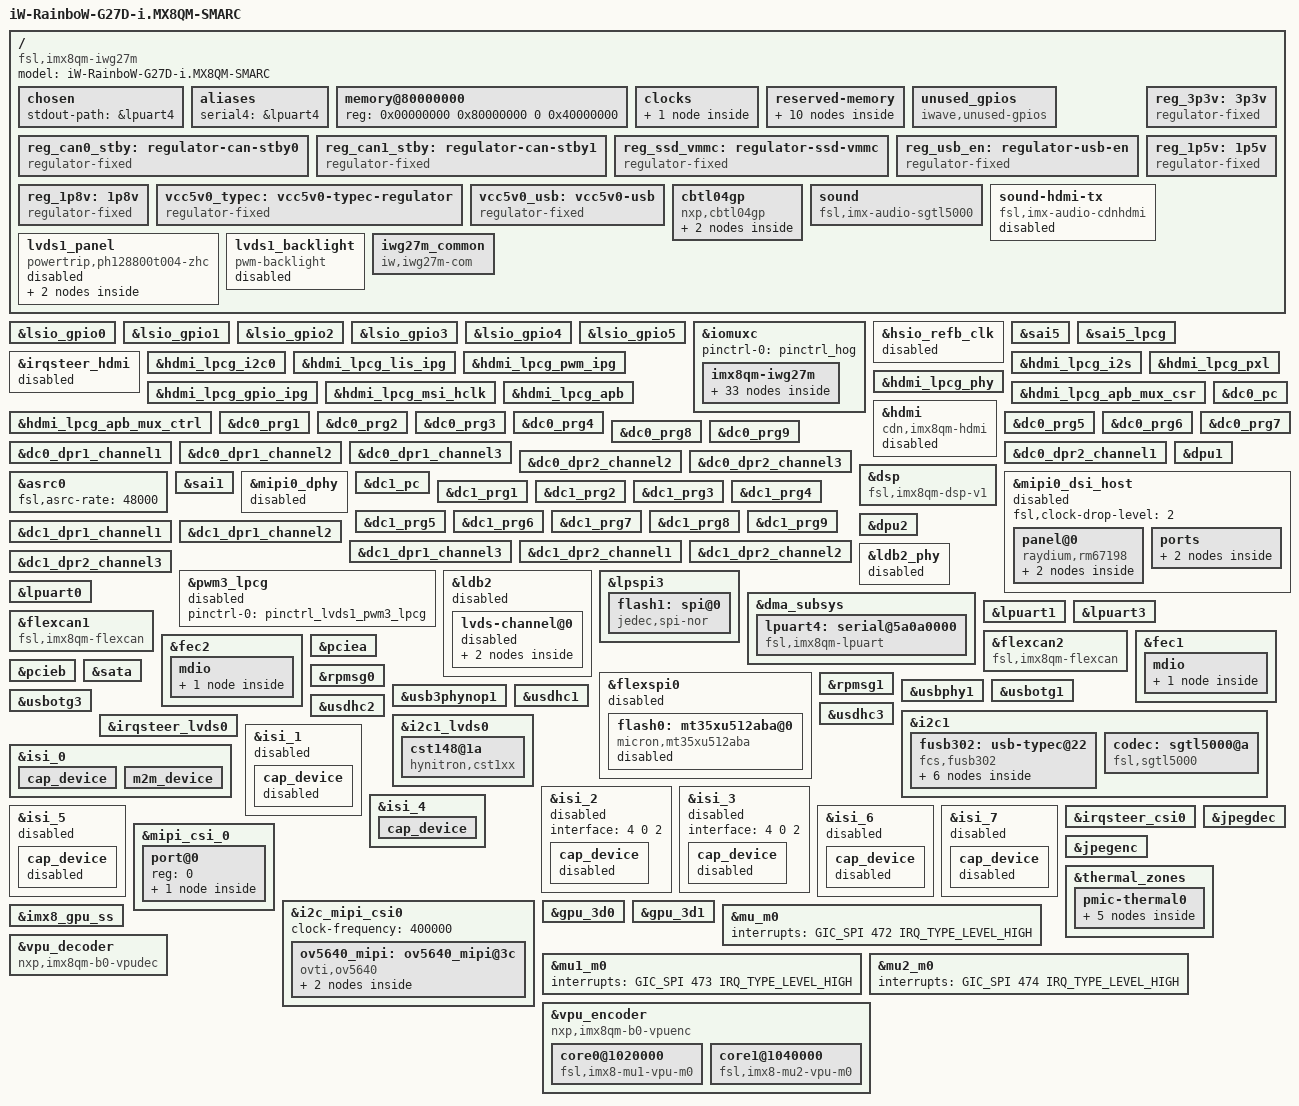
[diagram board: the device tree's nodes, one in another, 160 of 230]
/*
 * Copyright (c) 2020 iWave Systems Technologies Pvt. Ltd.
 *
 * This program is free software; you can redistribute it and/or
 * modify it under the terms of the GNU General Public License
 * as published by the Free Software Foundation; either version 2
 * of the License, or (at your option) any later version.
 *
 * This program is distributed in the hope that it will be useful,
 * but WITHOUT ANY WARRANTY; without even the implied warranty of
 * MERCHANTABILITY or FITNESS FOR A PARTICULAR PURPOSE.  See the
 * GNU General Public License for more details.
 */

#include <dt-bindings/usb/pd.h>
#include "imx8qm.dtsi"

/ {
	model = "iW-RainboW-G27D-i.MX8QM-SMARC";
	compatible = "fsl,imx8qm-iwg27m", "fsl,imx8qm";

	chosen {
                stdout-path = &lpuart4;
	};

	aliases {
		serial4 = &lpuart4;
	};

	memory@80000000 {
		device_type = "memory";
		reg = <0x00000000 0x80000000 0 0x40000000>;
	};

	clocks {
		#address-cells = <1>;
		#size-cells = <0>;

		audioclk: ext26Mz { /* SGTL5000: External Audio Clock */
			compatible = "fixed-clock";
			clock-frequency = <26000000>;
			reg=<0>;
			#clock-cells = <0>;
		};
	};

	reserved-memory {
		#address-cells = <2>;
		#size-cells = <2>;
		ranges;

		decoder_boot: decoder_boot@0x84000000 {
			no-map;
			reg = <0 0x84000000 0 0x2000000>;
		};
		encoder_boot: encoder_boot@0x86000000 {
			no-map;
			reg = <0 0x86000000 0 0x400000>;
		};
		/*
		 * reserved-memory layout
		 * 0x8800_0000 ~ 0x8FFF_FFFF is reserved for M4
		 * Shouldn't be used at A core and Linux side.
		 *
		 */
		m4_reserved: m4@0x88000000 {
			no-map;
			reg = <0 0x88000000 0 0x8000000>;
		};
		rpmsg_reserved: rpmsg@0x90000000 {
			no-map;
			reg = <0 0x90000000 0 0x400000>;
		};
		rpmsg_dma_reserved:rpmsg_dma@0x90400000 {
			compatible = "shared-dma-pool";
			no-map;
			reg = <0 0x90400000 0 0x100000>;
		};
		decoder_rpc: decoder_rpc@0x92000000 {
			no-map;
			reg = <0 0x92000000 0 0x200000>;
		};
		encoder_rpc: encoder_rpc@0x92200000 {
			no-map;
			reg = <0 0x92200000 0 0x200000>;
		};
		dsp_reserved: dsp@0x92400000 {
			no-map;
			reg = <0 0x92400000 0 0x2000000>;
		};
		encoder_reserved: encoder_reserved@0x94400000 {
			no-map;
			reg = <0 0x94400000 0 0x800000>;
		};

		/* global autoconfigured region for contiguous allocations */
		linux,cma {
			compatible = "shared-dma-pool";
			reusable;
			size = <0 0x3c000000>;
			alloc-ranges = <0 0x96000000 0 0x3c000000>;
			linux,cma-default;
		};

	};

	unused_gpios: unused_gpios { /* GPIO: Setting Unused GPIOs as input pins */
		compatible = "iwave,unused-gpios";
		pinctrl-names = "default";
		pinctrl-0 = <&pinctrl_unused_gpio>;
		status = "okay";  
	};

	reg_can0_stby: regulator-can-stby0 { /* CAN: CAN0 Standby Regulator */
		compatible = "regulator-fixed";
		regulator-name = "CAN0_STBY_1P8V";
		regulator-min-microvolt = <1800000>;
		regulator-max-microvolt = <1800000>;
		gpio = <&lsio_gpio1 27 GPIO_ACTIVE_HIGH>;
		regulator-always-on;
	};

	reg_can1_stby: regulator-can-stby1 { /* CAN: CAN1 Standby Regulator */
		compatible = "regulator-fixed";
		regulator-name = "CAN1_STBY_1P8V";
		regulator-min-microvolt = <1800000>;
		regulator-max-microvolt = <1800000>;
		gpio = <&lsio_gpio1 30 GPIO_ACTIVE_HIGH>;
		regulator-always-on;
	};

	reg_ssd_vmmc: regulator-ssd-vmmc { /* USDHC2: 3.3V VDD Enable Regulator */
		compatible = "regulator-fixed";
		regulator-name = "VDD_USDHC2_3P3V";
		regulator-min-microvolt = <3300000>;
		regulator-max-microvolt = <3300000>;
		gpio = <&lsio_gpio1 19 GPIO_ACTIVE_HIGH>;
		enable-active-high;
		regulator-always-on;
	};

	reg_usb_en: regulator-usb-en { /* USB: USB Hub Power Enable Regulator */
		compatible = "regulator-fixed";
		regulator-name = "VDD_USB_1P2V";
		regulator-min-microvolt = <1200000>;
		regulator-max-microvolt = <1200000>;
		regulator-type = "voltage";
		gpio = <&lsio_gpio1 21 GPIO_ACTIVE_HIGH>;
		enable-active-high;
		regulator-always-on;
	};

	reg_3p3v: 3p3v { /* Regulator: Fixed 3.3V Regulator */
		compatible = "regulator-fixed";
		regulator-name = "3P3V";
		regulator-min-microvolt = <3300000>;
		regulator-max-microvolt = <3300000>;
		regulator-always-on;
		regulator-boot-on;
	};

	reg_1p5v: 1p5v { /* Regulator: Fixed 1.5V Regulator */
		compatible = "regulator-fixed";
		regulator-name = "1P5V";
		regulator-min-microvolt = <1500000>;
		regulator-max-microvolt = <1500000>;
		regulator-always-on;
	};

	reg_1p8v: 1p8v { /* Regulator: Fixed 1.8V Regulator */
		compatible = "regulator-fixed";
		regulator-name = "1P8V";
		regulator-min-microvolt = <1800000>;
		regulator-max-microvolt = <1800000>;
		regulator-always-on;
	};

	vcc5v0_typec: vcc5v0-typec-regulator {
		compatible = "regulator-fixed";
		pinctrl-names = "default";
		regulator-name = "vcc5v0_typec";
		regulator-always-on;
		vin-supply = <&vcc5v0_usb>;
	};

	vcc5v0_usb: vcc5v0-usb {
		compatible = "regulator-fixed";
		regulator-name = "vcc5v0_usb";
		regulator-always-on;
		regulator-boot-on;
		regulator-min-microvolt = <5000000>;
		regulator-max-microvolt = <5000000>;
	};

	cbtl04gp {
		compatible = "nxp,cbtl04gp";
		pinctrl-names = "default";
		pinctrl-0 = <&pinctrl_typec_mux>;
		switch-gpios = <&lsio_gpio4 11 GPIO_ACTIVE_LOW>;
		orientation-switch;

		port {
			usb_data_ss: endpoint {
			remote-endpoint = <&typec_con_ss>;
			};
		};
        };

	sound { /* SGTL5000: Audio Codec */
		compatible = "fsl,imx-audio-sgtl5000";
		model = "sgtl5000-audio";
		ssi-controller = <&sai1>;
		audio-codec = <&codec>;
		audio-routing = "MIC_IN", "Mic Jack",
				"Mic Jack", "Mic Bias",
				"Headphone Jack", "HP_OUT",
				"LINE_IN", "Line In Jack";
	};

	sound-hdmi-tx { /* HDMI: HDMI TX Audio */
		compatible = "fsl,imx-audio-cdnhdmi";
		model = "imx-audio-hdmi-tx";
		audio-cpu = <&sai5>;
		protocol = <1>;
		hdmi-out;
		status = "disabled";
	};

	lvds1_panel { /* LVDS1: LVDS panel */
		compatible = "powertrip,ph128800t004-zhc";
		backlight = <&lvds1_backlight>;
		pinctrl-names = "default";
		pinctrl-0 = <&pinctrl_lvds1>;
		power-supply = <&reg_1p8v>;
		enable-gpios = <&lsio_gpio5 0 GPIO_ACTIVE_HIGH>;
		status = "disabled";

		port {
			panel_lvds1_in: endpoint {
				remote-endpoint = <&lvds1_out>;
			};
		};
	};

	lvds1_backlight: lvds1_backlight { /* LVDS1: LVDS Backlight Enable */
		compatible = "pwm-backlight";
		pwms = <&pwm3_lpcg 0 100000 0>;
		power-supply = <&reg_1p8v>;

		brightness-levels = < 0  1  2  3  4  5  6  7  8  9
				     10 11 12 13 14 15 16 17 18 19
				     20 21 22 23 24 25 26 27 28 29
				     30 31 32 33 34 35 36 37 38 39
				     40 41 42 43 44 45 46 47 48 49
				     50 51 52 53 54 55 56 57 58 59
				     60 61 62 63 64 65 66 67 68 69
				     70 71 72 73 74 75 76 77 78 79
				     80 81 82 83 84 85 86 87 88 89
				     90 91 92 93 94 95 96 97 98 99
				    100>;
		default-brightness-level = <100>;
		status = "disabled";
	};

	/* SoC Board Setttings : Setting Board Configuration GPIOs */
	iwg27m_common {
		compatible = "iw,iwg27m-com";
		pinctrl-names = "default";
		pinctrl-0 = <&pinctrl_board_cfg>;
		som-rev-gpios = <&lsio_gpio1 5 0>, <&lsio_gpio1 13 0>, <&lsio_gpio1 12 0>,  <&lsio_gpio1 11 0>,
			<&lsio_gpio0 6 0>, <&lsio_gpio0 7 0>, <&lsio_gpio0 11 0>;
		status = "okay";
	};
};

&lsio_gpio0 {
	status = "okay";
};

&lsio_gpio1 {
	status = "okay";
};

&lsio_gpio2 {
	status = "okay";
};

&lsio_gpio3 {
	status = "okay";
};

&lsio_gpio4 {
	status = "okay";
};

&lsio_gpio5 {
	status = "okay";
};

&iomuxc {
	pinctrl-names = "default";
	pinctrl-0 = <&pinctrl_hog>;

	imx8qm-iwg27m {
		pinctrl_hog: hoggrp { /* SDHC VSELECT Pin Configuration */
			fsl,pins = <
				IMX8QM_USDHC1_VSELECT_CONN_USDHC1_VSELECT		0x00000021
				IMX8QM_USDHC2_VSELECT_CONN_USDHC2_VSELECT		0x00000021
			>;
		};

		pinctrl_fec1: fec1grp { /* Ethernet0: IOMUX Pin Configuration */
			fsl,pins = <
				IMX8QM_COMP_CTL_GPIO_1V8_3V3_ENET_ENETB_PAD		0x000014a0
				IMX8QM_ENET0_MDC_CONN_ENET0_MDC				0x06000020
				IMX8QM_ENET0_MDIO_CONN_ENET0_MDIO			0x06000020
				IMX8QM_ENET0_RGMII_TX_CTL_CONN_ENET0_RGMII_TX_CTL	0x06000020
				IMX8QM_ENET0_RGMII_TXC_CONN_ENET0_RGMII_TXC		0x06000020
				IMX8QM_ENET0_RGMII_TXD0_CONN_ENET0_RGMII_TXD0		0x06000020
				IMX8QM_ENET0_RGMII_TXD1_CONN_ENET0_RGMII_TXD1		0x06000020
				IMX8QM_ENET0_RGMII_TXD2_CONN_ENET0_RGMII_TXD2		0x06000020
				IMX8QM_ENET0_RGMII_TXD3_CONN_ENET0_RGMII_TXD3		0x06000020
				IMX8QM_ENET0_RGMII_RXC_CONN_ENET0_RGMII_RXC		0x06000020
				IMX8QM_ENET0_RGMII_RX_CTL_CONN_ENET0_RGMII_RX_CTL	0x06000020
				IMX8QM_ENET0_RGMII_RXD0_CONN_ENET0_RGMII_RXD0		0x06000020
				IMX8QM_ENET0_RGMII_RXD1_CONN_ENET0_RGMII_RXD1		0x06000020
				IMX8QM_ENET0_RGMII_RXD2_CONN_ENET0_RGMII_RXD2		0x06000020
				IMX8QM_ENET0_RGMII_RXD3_CONN_ENET0_RGMII_RXD3		0x06000020
				IMX8QM_ENET0_REFCLK_125M_25M_CONN_ENET0_REFCLK_125M_25M	0x06000020
				IMX8QM_PCIE_CTRL0_CLKREQ_B_LSIO_GPIO4_IO27		0x06000021 /* Ethernet0 Interrupt */
				IMX8QM_PCIE_CTRL1_CLKREQ_B_LSIO_GPIO4_IO30		0x06000021 /* Ethernet0 Wake on LAN */
				IMX8QM_PCIE_CTRL1_WAKE_B_LSIO_GPIO4_IO31		0x06000021 /* Ethernet0 Reset */
			>;
		};

		pinctrl_fec2: fec2grp { /* Ethernet1: IOMUX Pin Configuration */
			fsl,pins = <
				IMX8QM_COMP_CTL_GPIO_1V8_3V3_ENET_ENETA_PAD		0x000014a0
				IMX8QM_ENET1_MDC_CONN_ENET1_MDC				0x06000020
				IMX8QM_ENET1_MDIO_CONN_ENET1_MDIO			0x06000020
				IMX8QM_ENET1_RGMII_TX_CTL_CONN_ENET1_RGMII_TX_CTL	0x00000060
				IMX8QM_ENET1_RGMII_TXC_CONN_ENET1_RGMII_TXC		0x00000060
				IMX8QM_ENET1_RGMII_TXD0_CONN_ENET1_RGMII_TXD0		0x00000060
				IMX8QM_ENET1_RGMII_TXD1_CONN_ENET1_RGMII_TXD1		0x00000060
				IMX8QM_ENET1_RGMII_TXD2_CONN_ENET1_RGMII_TXD2		0x00000060
				IMX8QM_ENET1_RGMII_TXD3_CONN_ENET1_RGMII_TXD3		0x00000060
				IMX8QM_ENET1_RGMII_RXC_CONN_ENET1_RGMII_RXC		0x00000060
				IMX8QM_ENET1_RGMII_RX_CTL_CONN_ENET1_RGMII_RX_CTL	0x00000060
				IMX8QM_ENET1_RGMII_RXD0_CONN_ENET1_RGMII_RXD0		0x00000060
				IMX8QM_ENET1_RGMII_RXD1_CONN_ENET1_RGMII_RXD1		0x00000060
				IMX8QM_ENET1_RGMII_RXD2_CONN_ENET1_RGMII_RXD2		0x00000060
				IMX8QM_ENET1_RGMII_RXD3_CONN_ENET1_RGMII_RXD3		0x00000060
				IMX8QM_ENET1_REFCLK_125M_25M_CONN_ENET1_REFCLK_125M_25M	0x00000060
				IMX8QM_MIPI_DSI1_I2C0_SCL_LSIO_GPIO1_IO20		0x06000021 /* Ethernet1 Reset */
				IMX8QM_MIPI_DSI0_I2C0_SCL_LSIO_GPIO1_IO16		0x06000021 /* Ethernet1 Wake on LAN */
				IMX8QM_MIPI_DSI0_I2C0_SDA_LSIO_GPIO1_IO17		0x06000021 /* Ethernet1 Interrupt */
			>;
		};

		pinctrl_flexspi0: flexspi0grp { /* FLEXSPI: MT35XU512ABA Octa-SPI IOMUX Pin Configuration */
			fsl,pins = <
				IMX8QM_QSPI0A_DATA0_LSIO_QSPI0A_DATA0			0x06000021
				IMX8QM_QSPI0A_DATA1_LSIO_QSPI0A_DATA1			0x06000021
				IMX8QM_QSPI0A_DATA2_LSIO_QSPI0A_DATA2			0x06000021
				IMX8QM_QSPI0A_DATA3_LSIO_QSPI0A_DATA3			0x06000021
				IMX8QM_QSPI0A_DQS_LSIO_QSPI0A_DQS			0x06000021
				IMX8QM_QSPI0A_SS0_B_LSIO_QSPI0A_SS0_B			0x06000021
				IMX8QM_QSPI0A_SS1_B_LSIO_QSPI0A_SS1_B			0x06000021
				IMX8QM_QSPI0A_SCLK_LSIO_QSPI0A_SCLK			0x06000021
				IMX8QM_QSPI0B_SCLK_LSIO_QSPI0B_SCLK			0x06000021
				IMX8QM_QSPI0B_DATA0_LSIO_QSPI0B_DATA0			0x06000021
				IMX8QM_QSPI0B_DATA1_LSIO_QSPI0B_DATA1			0x06000021
				IMX8QM_QSPI0B_DATA2_LSIO_QSPI0B_DATA2			0x06000021
				IMX8QM_QSPI0B_DATA3_LSIO_QSPI0B_DATA3			0x06000021
				IMX8QM_QSPI0B_DQS_LSIO_QSPI0B_DQS			0x06000021
				IMX8QM_QSPI0B_SS0_B_LSIO_QSPI0B_SS0_B			0x06000021
				IMX8QM_QSPI0B_SS1_B_LSIO_QSPI0B_SS1_B			0x06000021
			>;
		};

		pinctrl_lpspi3: lpspi3grp { /* LPSPI3: LPSPI3 IOMUX Pin Configuration */
			fsl,pins = <
				IMX8QM_SPI3_SCK_DMA_SPI3_SCK				0x0600004c
				IMX8QM_SPI3_SDO_DMA_SPI3_SDO				0x0600004c
				IMX8QM_SPI3_SDI_DMA_SPI3_SDI				0x0600004c
				IMX8QM_SPI3_CS0_LSIO_GPIO2_IO20				0x00000021
				IMX8QM_SPI3_CS1_DMA_SPI3_CS1				0x0600004c
			>;
		};

		pinctrl_flexcan1: flexcan0grp { /* CAN: FLEXCAN1 IOMUX Pin Configuration */
			fsl,pins = <
				IMX8QM_FLEXCAN0_TX_DMA_FLEXCAN0_TX			0x00000021
				IMX8QM_FLEXCAN0_RX_DMA_FLEXCAN0_RX			0x00000021
				IMX8QM_MIPI_CSI0_GPIO0_00_LSIO_GPIO1_IO27		0x00000021 /* FLEXCAN1 Power Down GPIO */
			>;
		};

		pinctrl_flexcan2: flexcan1grp { /* CAN: FLEXCAN2 IOMUX Pin Configuration */
			fsl,pins = <
				IMX8QM_FLEXCAN1_TX_DMA_FLEXCAN1_TX			0x00000021
				IMX8QM_FLEXCAN1_RX_DMA_FLEXCAN1_RX			0x00000021
				IMX8QM_MIPI_CSI1_GPIO0_00_LSIO_GPIO1_IO30		0x00000021 /* FLEXCAN2 Power Down GPIO */ 
			>;
		};

		pinctrl_lpuart0: lpuart0grp { /* LPUART0: DATA UART IOMUX Pin Configuration */
			fsl,pins = <
				IMX8QM_UART0_RX_DMA_UART0_RX				0x06000020
				IMX8QM_UART0_TX_DMA_UART0_TX				0x06000020
				IMX8QM_UART0_RTS_B_DMA_UART0_RTS_B			0x06000020
				IMX8QM_UART0_CTS_B_DMA_UART0_CTS_B			0x06000020
			>;
		};

		pinctrl_lpuart1: lpuart1grp { /* LPUART1: Bluetooth IOMUX Pin Configuration */
			fsl,pins = <
				IMX8QM_UART1_RX_DMA_UART1_RX				0x06000020
				IMX8QM_UART1_TX_DMA_UART1_TX				0x06000020
				IMX8QM_UART1_CTS_B_DMA_UART1_CTS_B			0x06000020
				IMX8QM_UART1_RTS_B_DMA_UART1_RTS_B			0x06000020
			>;
		};

		pinctrl_lpuart3: lpuart3grp { /* LPUART3: Debug UART IOMUX Pin Configuration */
			fsl,pins = <
				IMX8QM_M41_GPIO0_00_DMA_UART3_RX			0x06000020
				IMX8QM_M41_GPIO0_01_DMA_UART3_TX			0x06000020
			>;
		};

		pinctrl_lpuart4: lpuart4ggrp { /* LPUART4: Debug UART IOMUX Pin Configuration */
			fsl,pins = <
				IMX8QM_M40_GPIO0_00_DMA_UART4_RX			0x06000020
				IMX8QM_M40_GPIO0_01_DMA_UART4_TX			0x06000020
			>;
		};

		pinctrl_sai1: sai1grp { /* SGTL5000: SAI Audio IOMUX Pin Configuration */
			fsl,pins = <
				IMX8QM_SAI1_RXD_AUD_SAI1_RXD				0xc600004c
				IMX8QM_SAI1_TXC_AUD_SAI1_TXC				0xc600004c
				IMX8QM_SAI1_TXD_AUD_SAI1_TXD				0xc600004c
				IMX8QM_SAI1_TXFS_AUD_SAI1_TXFS				0xc600004c
			>;
		};

		pinctrl_hp_mic_detect: hp_mic_detect { /* SGTL5000: IOMUX Pin Configuration */
			fsl,pins = <
				IMX8QM_SIM0_IO_LSIO_GPIO0_IO02				0x00000021 /* HeadPhone Detect GPIO */
				IMX8QM_SIM0_GPIO0_00_LSIO_GPIO0_IO05			0x00000021 /* MicroPhone Detect GPIO */
				IMX8QM_MCLK_OUT0_AUD_ACM_MCLK_OUT0			0x0600004c
			>;
		};

		pinctrl_lpi2c1: lpi2c1grp { /* I2C1: IOMUX Pin Configuration */
			fsl,pins = <
				IMX8QM_GPT0_CLK_DMA_I2C1_SCL				0xc600004c
				IMX8QM_GPT0_CAPTURE_DMA_I2C1_SDA			0xc600004c
			>;
		};

		pinctrl_i2c1_lvds0: i2c1_lvds0grp { /* I2C1_LVDS0: Touch IOMUX Pin Configuration */
			fsl,pins = <
				IMX8QM_LVDS0_I2C0_SCL_LVDS0_I2C0_SCL			0xc600004c
				IMX8QM_LVDS0_I2C0_SDA_LVDS0_I2C0_SDA			0xc600004c
			>;
		};

		pinctrl_ts_active_iwg27m: touch { /* Touch: IOMUX Pin Configuration */
			fsl,pins = <
				IMX8QM_SIM0_RST_LSIO_GPIO0_IO01				0x00000021 /* Touch IRQ GPIO */
				IMX8QM_M41_I2C0_SCL_LSIO_GPIO0_IO10			0x00000021 /* Touch Reset GPIO */
			>;
		};

		pinctrl_pciea: pcieagrp{ /* PCIE: IOMUX Pin Configuration */
			fsl,pins = <
				IMX8QM_SIM0_POWER_EN_LSIO_GPIO0_IO04			0x00000021 /* PCIE W_DISABLE GPIO */
				IMX8QM_PCIE_CTRL0_WAKE_B_LSIO_GPIO4_IO28		0x00000021 /* PCIE Wake GPIO */
				IMX8QM_PCIE_CTRL0_PERST_B_LSIO_GPIO4_IO29		0x00000021 /* PCIE Reset GPIO */
			>;
		};

		pinctrl_type_c: usbtypec { /* USB3.0: FUSB Type-C IOMUX Pin Configuration */
			fsl,pins = <
				IMX8QM_SIM0_CLK_LSIO_GPIO0_IO00				0x00000021 /* Type-C IRQ GPIO */
			>;
		};

		pinctrl_typec_mux: usbtypec_ss { /* USB3.0: FUSB Type-C IOMUX Pin Configuration */
			fsl,pins = <
				IMX8QM_USDHC2_WP_LSIO_GPIO4_IO11			0x00000021 /* Type-C USB SS select GPIO */
			>;
		};

		pinctrl_usbotg1: usbotg1 { /* USBOTG1: USB OTG IOMUX Pin Configuration */
			fsl,pins = <
				IMX8QM_USB_SS3_TC0_LSIO_GPIO4_IO03			0x00000021 /* USB2.0 OTG Power GPIO */
			>;
		};

		pinctrl_usbotg3: usbotg3 { /* USBOTG3: USB Hub IOMUX Pin COnfiguration */
			fsl,pins = <
				IMX8QM_MIPI_DSI1_I2C0_SDA_LSIO_GPIO1_IO21		0x00000021 /* USB3.0 Hub Reset GPIO */
			>;
		};

		pinctrl_usdhc1: usdhc1grp { /* USDHC1: EMMC IOMUX Pin Configuration */
			fsl,pins = <
				IMX8QM_EMMC0_CLK_CONN_EMMC0_CLK				0x06000041
				IMX8QM_EMMC0_CMD_CONN_EMMC0_CMD				0x00000021
				IMX8QM_EMMC0_DATA0_CONN_EMMC0_DATA0			0x00000021
				IMX8QM_EMMC0_DATA1_CONN_EMMC0_DATA1			0x00000021
				IMX8QM_EMMC0_DATA2_CONN_EMMC0_DATA2			0x00000021
				IMX8QM_EMMC0_DATA3_CONN_EMMC0_DATA3			0x00000021
				IMX8QM_EMMC0_DATA4_CONN_EMMC0_DATA4			0x00000021
				IMX8QM_EMMC0_DATA5_CONN_EMMC0_DATA5			0x00000021
				IMX8QM_EMMC0_DATA6_CONN_EMMC0_DATA6			0x00000021
				IMX8QM_EMMC0_DATA7_CONN_EMMC0_DATA7			0x00000021
				IMX8QM_EMMC0_STROBE_CONN_EMMC0_STROBE			0x00000041
				IMX8QM_EMMC0_RESET_B_CONN_EMMC0_RESET_B			0x00000021
			>;
		};

		pinctrl_usdhc2_gpio: usdhc2grpgpio { /* USDHC2: Standard SD IOMUX Pin Configuration */
			fsl,pins = <
				IMX8QM_MIPI_DSI1_GPIO0_00_LSIO_GPIO1_IO22		0x00000021 /* Standard SD Write Protect */
				IMX8QM_MIPI_DSI1_GPIO0_01_LSIO_GPIO1_IO23		0x00000021 /* Standard SD Card Detect */
				IMX8QM_MIPI_DSI0_GPIO0_01_LSIO_GPIO1_IO19		0x00000021 /* Standard SD Power Enable */
			>;
		};

		pinctrl_usdhc2: usdhc2grp {
			fsl,pins = <
				IMX8QM_USDHC1_CLK_CONN_USDHC1_CLK			0x06000041
				IMX8QM_USDHC1_CMD_CONN_USDHC1_CMD			0x00000021
				IMX8QM_USDHC1_DATA0_CONN_USDHC1_DATA0			0x00000021
				IMX8QM_USDHC1_DATA1_CONN_USDHC1_DATA1			0x00000021
				IMX8QM_USDHC1_DATA2_CONN_USDHC1_DATA2			0x00000021
				IMX8QM_USDHC1_DATA3_CONN_USDHC1_DATA3			0x00000021
			>;
		};

		pinctrl_usdhc3_gpio: usdhc3grpgpio { /* USDHC3: IOMUX Pin Configuration */
			fsl,pins = <
				IMX8QM_ESAI0_TX2_RX3_LSIO_GPIO2_IO28			0x00000021 /* WIFI IRQ */
				IMX8QM_ESAI0_TX3_RX2_LSIO_GPIO2_IO29			0x00000021 /* WIFI RST */
				IMX8QM_ESAI0_TX4_RX1_LSIO_GPIO2_IO30			0x00000021 /* WIFI CORE_PDn */
				IMX8QM_USDHC2_CD_B_LSIO_GPIO4_IO12			0x00000021 /* SD Card Detect GPIO */	
				IMX8QM_SPI0_CS0_LSIO_GPIO3_IO05				0x00000021 /* WIFI WL_DEV_WAKE */
                                IMX8QM_SAI1_RXC_LSIO_GPIO3_IO12				0x00000021 /* WIFI WL_HOST_WAKE */
				IMX8QM_USDHC1_RESET_B_LSIO_GPIO4_IO07			0x00000021 /* WIFI PDn */
				IMX8QM_ESAI0_TX1_LSIO_GPIO2_IO27			0x00000021 /* BT_DEV_WAKE */
				IMX8QM_MCLK_IN0_LSIO_GPIO3_IO00				0x00000021 /* BT_HOST_WAKE */
			>;
		};

		pinctrl_usdhc3: usdhc3grp {
			fsl,pins = <
				IMX8QM_USDHC2_CLK_CONN_USDHC2_CLK			0x06000041
				IMX8QM_USDHC2_CMD_CONN_USDHC2_CMD			0x00000021
				IMX8QM_USDHC2_DATA0_CONN_USDHC2_DATA0			0x00000021
				IMX8QM_USDHC2_DATA1_CONN_USDHC2_DATA1			0x00000021
				IMX8QM_USDHC2_DATA2_CONN_USDHC2_DATA2			0x00000021
				IMX8QM_USDHC2_DATA3_CONN_USDHC2_DATA3			0x00000021
			>;
		};

		pinctrl_lvds1: lvds1grp { /* LVDS1: LVDS panel IOMUX Pin Configuration */
			fsl,pins = <
				IMX8QM_PCIE_CTRL1_PERST_B_LSIO_GPIO5_IO00		0x00000021 /* LVDS Power Enable GPIO */
			>;
		};

		pinctrl_lvds1_pwm3_lpcg: lvds1pwm3_lpcggrp { /* LVDS1: LVDS PWM IOMUX Pin Configuration */
			fsl,pins = <
				IMX8QM_GPT0_COMPARE_LSIO_PWM3_OUT			0x00000020
			>;
		};

		pinctrl_mipi_csi0: mipicsi0grp{ /* MIPI_CSI0: Camera MCLOCK IOMUX Pin Configuration */
			fsl,pins = <
				IMX8QM_MIPI_CSI0_MCLK_OUT_MIPI_CSI0_ACM_MCLK_OUT	0xC0000041
			>;
		};

		pinctrl_mipi_dsi: mipidsi { /* MIPI_DSI: LCD IOMUX Pin Configuration */
			fsl,pins = <
				IMX8QM_SIM0_PD_LSIO_GPIO0_IO03				0x00000021 /* MIPI-DSI Reset GPIO */
			>;
		};

		pinctrl_sata: sata { /* SATA: IOMUX Pin Configuration */
			fsl,pins = <
				IMX8QM_MIPI_DSI0_GPIO0_00_LSIO_GPIO1_IO18		0x00000021 /* SATA ACT LED GPIO */
			>;
		};

		pinctrl_board_cfg: brd_cfg { /* SoC Board Settings: IOMUX Pin Configuration */
			fsl,pins = <
				IMX8QM_LVDS0_GPIO01_LSIO_GPIO1_IO05			0x00000021
				IMX8QM_LVDS1_I2C0_SDA_LSIO_GPIO1_IO13			0x00000021
				IMX8QM_LVDS1_I2C0_SCL_LSIO_GPIO1_IO12			0x00000021
				IMX8QM_LVDS1_GPIO01_LSIO_GPIO1_IO11			0x00000021
				IMX8QM_M40_I2C0_SCL_LSIO_GPIO0_IO06			0x00000021
				IMX8QM_M40_I2C0_SDA_LSIO_GPIO0_IO07			0x00000021
				IMX8QM_M41_I2C0_SDA_LSIO_GPIO0_IO11			0x00000021
			>;
		};

		pinctrl_unused_gpio: unused_gpiogrp{ /* GPIO: Unused GPIOs IOMUX Pin Configuration */
			fsl,pins = <
				IMX8QM_LVDS0_GPIO00_LSIO_GPIO1_IO04			0x00000021
				IMX8QM_LVDS0_I2C1_SCL_LSIO_GPIO1_IO08			0x00000021
				IMX8QM_LVDS1_GPIO00_LSIO_GPIO1_IO10			0x00000021
				IMX8QM_LVDS1_I2C1_SCL_LSIO_GPIO1_IO14			0x00000021
				IMX8QM_LVDS1_I2C1_SDA_LSIO_GPIO1_IO15			0x00000021
				IMX8QM_MIPI_CSI1_MCLK_OUT_LSIO_GPIO1_IO29		0x00000021
				IMX8QM_MIPI_CSI1_I2C0_SCL_LSIO_GPIO2_IO00		0x00000021
				IMX8QM_MIPI_CSI1_I2C0_SDA_LSIO_GPIO2_IO01		0x00000021
				IMX8QM_HDMI_TX0_TS_SCL_LSIO_GPIO2_IO02			0x00000021
				IMX8QM_HDMI_TX0_TS_SDA_LSIO_GPIO2_IO03			0x00000021
				IMX8QM_ESAI1_FSR_LSIO_GPIO2_IO04			0x00000021
				IMX8QM_ESAI1_FST_LSIO_GPIO2_IO05			0x00000021
				IMX8QM_ESAI1_SCKR_LSIO_GPIO2_IO06			0x00000021
				IMX8QM_ESAI1_SCKT_LSIO_GPIO2_IO07			0x00000021
				IMX8QM_ESAI1_TX0_LSIO_GPIO2_IO08			0x00000021
				IMX8QM_ESAI1_TX1_LSIO_GPIO2_IO09			0x00000021
				IMX8QM_ESAI1_TX2_RX3_LSIO_GPIO2_IO10			0x00000021
				IMX8QM_ESAI1_TX3_RX2_LSIO_GPIO2_IO11			0x00000021
				IMX8QM_ESAI1_TX4_RX1_LSIO_GPIO2_IO12			0x00000021
				IMX8QM_ESAI1_TX5_RX0_LSIO_GPIO2_IO13			0x00000021
				IMX8QM_SPDIF0_RX_LSIO_GPIO2_IO14			0x00000021
				IMX8QM_SPDIF0_TX_LSIO_GPIO2_IO15			0x00000021
				IMX8QM_SPDIF0_EXT_CLK_LSIO_GPIO2_IO16			0x00000021
				IMX8QM_ESAI0_FSR_LSIO_GPIO2_IO22			0x00000021
				IMX8QM_ESAI0_SCKR_LSIO_GPIO2_IO24			0x00000021
				IMX8QM_SPI0_SCK_LSIO_GPIO3_IO02				0x00000021
				IMX8QM_SPI0_SDO_LSIO_GPIO3_IO03				0x00000021
				IMX8QM_SPI0_SDI_LSIO_GPIO3_IO04				0x00000021
				IMX8QM_SPI0_CS1_LSIO_GPIO3_IO06				0x00000021
				IMX8QM_SPI2_CS1_LSIO_GPIO3_IO11				0x00000021
				IMX8QM_SAI1_RXFS_LSIO_GPIO3_IO14			0x00000021
				IMX8QM_ADC_IN4_LSIO_GPIO3_IO22				0x00000021
				IMX8QM_ADC_IN5_LSIO_GPIO3_IO23				0x00000021
				IMX8QM_ADC_IN6_LSIO_GPIO3_IO24				0x00000021
				IMX8QM_ADC_IN7_LSIO_GPIO3_IO25				0x00000021
				IMX8QM_MLB_SIG_LSIO_GPIO3_IO26				0x00000021
				IMX8QM_MLB_CLK_LSIO_GPIO3_IO27				0x00000021
				IMX8QM_MLB_DATA_LSIO_GPIO3_IO28				0x00000021
				IMX8QM_FLEXCAN2_RX_LSIO_GPIO4_IO01			0x00000021
				IMX8QM_FLEXCAN2_TX_LSIO_GPIO4_IO02			0x00000021
				IMX8QM_USB_SS3_TC2_LSIO_GPIO4_IO05			0x00000021
				IMX8QM_USDHC2_RESET_B_LSIO_GPIO4_IO09			0x00000021
				IMX8QM_QSPI1A_SS0_B_LSIO_GPIO4_IO19			0x00000021
				IMX8QM_QSPI1A_SS1_B_LSIO_GPIO4_IO20			0x00000021
				IMX8QM_QSPI1A_SCLK_LSIO_GPIO4_IO21			0x00000021
				IMX8QM_QSPI1A_DQS_LSIO_GPIO4_IO22			0x00000021
				IMX8QM_QSPI1A_DATA3_LSIO_GPIO4_IO23			0x00000021
				IMX8QM_QSPI1A_DATA2_LSIO_GPIO4_IO24			0x00000021
				IMX8QM_QSPI1A_DATA1_LSIO_GPIO4_IO25			0x00000021
				IMX8QM_QSPI1A_DATA0_LSIO_GPIO4_IO26			0x00000021
				IMX8QM_USB_HSIC0_DATA_LSIO_GPIO5_IO01			0x00000021
				IMX8QM_USB_HSIC0_STROBE_LSIO_GPIO5_IO02			0x00000021
				IMX8QM_USDHC1_DATA4_LSIO_GPIO5_IO19			0x00000021
				IMX8QM_USDHC1_DATA5_LSIO_GPIO5_IO20			0x00000021
				IMX8QM_USDHC1_DATA6_LSIO_GPIO5_IO21			0x00000021
				IMX8QM_USDHC1_DATA7_LSIO_GPIO5_IO22			0x00000021
			>;
		};
	};
};

&hsio_refb_clk {
	status = "disabled";
};

&sai5 {
	status = "okay";
};

&sai5_lpcg {
        status = "okay";
};

&irqsteer_hdmi {
	status = "disabled";
};

&hdmi_lpcg_i2c0 {
	status = "okay";
};

&hdmi_lpcg_lis_ipg {
	status = "okay";
};

&hdmi_lpcg_pwm_ipg {
	status = "okay";
};

&hdmi_lpcg_i2s {
	status = "okay";
};

&hdmi_lpcg_gpio_ipg {
	status = "okay";
};

&hdmi_lpcg_msi_hclk {
	status = "okay";
};

&hdmi_lpcg_pxl {
	status = "okay";
};

&hdmi_lpcg_phy {
	status = "okay";
};

&hdmi_lpcg_apb_mux_csr {
	status = "okay";
};

&hdmi_lpcg_apb_mux_ctrl {
	status = "okay";
};

&hdmi_lpcg_apb {
	status = "okay";
};

&hdmi {
        compatible = "cdn,imx8qm-hdmi";
        lane-mapping = <0x93>;
	/* IWG27M: HDMI-DDC: Workaround for R3.X SOM DDC IO Voltage level */
        fsl,no_edid;
	status = "disabled";
};

&dc0_pc {
	status = "okay";
};

&dc0_prg1 {
	status = "okay";
};

&dc0_prg2 {
	status = "okay";
};

&dc0_prg3 {
	status = "okay";
};

&dc0_prg4 {
	status = "okay";
};

&dc0_prg5 {
	status = "okay";
};

&dc0_prg6 {
	status = "okay";
};

&dc0_prg7 {
	status = "okay";
};

&dc0_prg8 {
	status = "okay";
};

&dc0_prg9 {
	status = "okay";
};

&dc0_dpr1_channel1 {
	status = "okay";
};

&dc0_dpr1_channel2 {
	status = "okay";
};

&dc0_dpr1_channel3 {
	status = "okay";
};

&dc0_dpr2_channel1 {
	status = "okay";
};

&dc0_dpr2_channel2 {
	status = "okay";
};

&dc0_dpr2_channel3 {
	status = "okay";
};

&dpu1 {
	status = "okay";
};

&dsp {
	compatible = "fsl,imx8qm-dsp-v1";
	status = "okay";
};

&asrc0 {
	fsl,asrc-rate  = <48000>;
	status = "okay";
};

&sai1 { /* SGTL5000: Serial Audio Interface for SGTL5000 Audio Codec */
	assigned-clocks = <&clk IMX_SC_R_AUDIO_PLL_0 IMX_SC_PM_CLK_PLL>,
		<&clk IMX_SC_R_AUDIO_PLL_0 IMX_SC_PM_CLK_SLV_BUS>,
		<&clk IMX_SC_R_AUDIO_PLL_0 IMX_SC_PM_CLK_MST_BUS>,
		<&sai1_lpcg 0>; /* FIXME: should be sai1, original code is 0 */
	assigned-clock-rates = <786432000>, <49152000>, <12288000>, <49152000>;
	pinctrl-names = "default";
	pinctrl-0 = <&pinctrl_sai1>;
	status = "okay";
};

&mipi0_dphy { /* MIPI_DSI1: MIPI DSI Phy */
        status = "disabled";
};

&mipi0_dsi_host { /* MIPI_DSI1: MIPI DSI Host */
	fsl,clock-drop-level = <2>;
	status = "disabled";

	panel@0 {
		#address-cells = <1>;
		#size-cells = <0>;

		compatible = "raydium,rm67198";
		pinctrl-0 = <&pinctrl_mipi_dsi>;
		pinctrl-names = "default";
		reset-gpios = <&lsio_gpio0 3 GPIO_ACTIVE_LOW>;
		reg = <0>;
		dsi-lanes = <4>;
		video-mode = <2>;
		width-mm = <68>;
		height-mm = <121>;
		v3p3-supply = <&reg_3p3v>;
		v1p8-supply = <&reg_1p8v>;

		port@0 {
			reg = <0>;
			panel0_in: endpoint {
				remote-endpoint = <&mipi0_panel_out>;
			};
		};
	};

	ports {
		port@1 {
			reg = <1>;
			mipi0_panel_out: endpoint {
				remote-endpoint = <&panel0_in>;
			};
		};
	};
};

&dc1_pc {
	status = "okay";
};

&dc1_prg1 {
	status = "okay";
};

&dc1_prg2 {
	status = "okay";
};

&dc1_prg3 {
	status = "okay";
};

&dc1_prg4 {
	status = "okay";
};

&dc1_prg5 {
	status = "okay";
};

&dc1_prg6 {
	status = "okay";
};

&dc1_prg7 {
	status = "okay";
};

&dc1_prg8 {
	status = "okay";
};

&dc1_prg9 {
	status = "okay";
};

&dc1_dpr1_channel1 {
	status = "okay";
};

&dc1_dpr1_channel2 {
	status = "okay";
};

&dc1_dpr1_channel3 {
	status = "okay";
};

&dc1_dpr2_channel1 {
	status = "okay";
};

&dc1_dpr2_channel2 {
	status = "okay";
};

&dc1_dpr2_channel3 {
	status = "okay";
};

&dpu2 {
	status = "okay";
};

&pwm3_lpcg { /* LVDS1: LVDS PWM3 Control */
	pinctrl-names = "default";
	#pwm-cells = <2>;
	pinctrl-0 = <&pinctrl_lvds1_pwm3_lpcg>;
	status = "disabled";
};

&ldb2_phy { /* LVDS1: LVDS LDB Phy */
	status = "disabled";
};

&ldb2 { /* LVDS1: LVDS Channel-0 Port Enable */
	status = "disabled";

	lvds-channel@0 {
		fsl,data-mapping = "spwg";
		fsl,data-width = <24>;
		status = "disabled";
		port@1 {
			reg = <1>;

			lvds1_out: endpoint {
				remote-endpoint = <&panel_lvds1_in>;
			};
		};
	};
};

&lpspi3 { /* LPSPI3: SPI Flash Device */
        pinctrl-names = "default";
        pinctrl-0 = <&pinctrl_lpspi3>;
        cs-gpios = <&lsio_gpio2 20 GPIO_ACTIVE_LOW>;
        fsl,spi-num-chipselects = <1>;
        assigned-clock-rates = <80000000>;
        #address-cells = <1>;
        #size-cells = <0>;
	dma-names = "tx","rx";
	dmas = <&edma2 7 0 0>,
		<&edma2 6 0 1>;
	status = "okay";

	flash1: spi@0 { /* SST25WF020A SPI Flash */
		#address-cells = <1>;
		#size-cells = <1>;
		compatible = "jedec,spi-nor", "is25wp016d";
                spi-max-frequency = <40000000>;
                reg = <0>;
                spi-tx-bus-width = <1>;
                spi-rx-bus-width = <1>;
                m25p,fast-read;
		status = "okay";
	};
};

&dma_subsys {
	lpuart4: serial@5a0a0000 {
		compatible = "fsl,imx8qm-lpuart", "fsl,imx8qxp-lpuart";
		reg = <0x5a0a0000 0x1000>;
		interrupts = <GIC_SPI 349 IRQ_TYPE_LEVEL_HIGH>;
		interrupt-parent = <&gic>;
		clocks = <&uart4_lpcg 1>, <&uart4_lpcg 0>;
		clock-names = "ipg", "baud";
		assigned-clocks = <&clk IMX_SC_R_UART_4 IMX_SC_PM_CLK_PER>;
		assigned-clock-rates = <80000000>;
		power-domains = <&pd IMX_SC_R_UART_4>;
		power-domain-names = "uart";
		dma-names = "tx","rx";
		dmas = <&edma2 21 0 0>,
			<&edma2 20 0 1>;
	};
};

&lpuart0 { /* LPUART0: DATA UART */
	pinctrl-names = "default";
	pinctrl-0 = <&pinctrl_lpuart0>;
	dma-names = "tx","rx";
	power-domains = <&pd IMX_SC_R_UART_0>;
	dmas = <&edma2 13 0 0>,
	       <&edma2 12 0 1>;
	status = "okay";
};

&lpuart1 { /* LPUART1: Bluetooth */
	pinctrl-names = "default";
	pinctrl-0 = <&pinctrl_lpuart1>;
	port-number = <1>;
	status = "okay";
};

&lpuart3 { /* LPUART3: DATA UART */
        pinctrl-names = "default";
        pinctrl-0 = <&pinctrl_lpuart3>;
	power-domains = <&pd IMX_SC_R_UART_3>;
	dmas = <&edma2 19 0 0>,
	       <&edma2 18 0 1>;
        status = "okay";
};

&lpuart4 { /* LPUART4: Debug UART */
        pinctrl-names = "default";
        pinctrl-0 = <&pinctrl_lpuart4>;
	status = "okay";
};

&flexcan1 { /* CAN: FLEXCAN1 */
	pinctrl-names = "default";
	compatible = "fsl,imx8qm-flexcan"; 
	pinctrl-0 = <&pinctrl_flexcan1>;
	xceiver-supply = <&reg_can0_stby>;
	status = "okay";
};

&flexcan2 { /* CAN: FLEXCAN2 */
	pinctrl-names = "default";
	pinctrl-0 = <&pinctrl_flexcan2>;
	compatible = "fsl,imx8qm-flexcan"; 
	xceiver-supply = <&reg_can1_stby>;
	status = "okay";
};

&fec1 { /* FEC1: AR8031 PHY ENET 0 */
	pinctrl-names = "default";
	pinctrl-0 = <&pinctrl_fec1>;
	phy-mode = "rgmii-txid";
	phy-handle = <&ethphy0>;
	phy-reset-gpios = <&lsio_gpio4 31 GPIO_ACTIVE_LOW>;
	fsl,magic-packet;
	fsl,rgmii_rxc_dly;
	fsl,mii-exclusive;
	nvmem-cells = <&fec_mac0>;
	nvmem-cell-names = "mac-address";
	status = "okay";

	mdio {
		#address-cells = <1>;
		#size-cells = <0>;

		ethphy0: ethernet-phy@0 {
			compatible = "ethernet-phy-ieee802.3-c22";
			reg = <4>;
			at803x,eee-disabled;
			at803x,vddio-1p8v;
		};
	};
};

&fec2 { /* FEC2: AR8031 PHY ENET 1 */
	pinctrl-names = "default";
	pinctrl-0 = <&pinctrl_fec2>;
	phy-mode = "rgmii-txid";
	phy-handle = <&ethphy1>;
	phy-reset-gpios = <&lsio_gpio1 20 GPIO_ACTIVE_LOW>;
	fsl,magic-packet;
	fsl,rgmii_rxc_dly;
	fsl,mii-exclusive;
	nvmem-cells = <&fec_mac1>;
	nvmem-cell-names = "mac-address";
	status = "okay";

	mdio {
		#address-cells = <1>;
		#size-cells = <0>;

		ethphy1: ethernet-phy@1 {
			compatible = "ethernet-phy-ieee802.3-c22";
			reg = <5>;
			at803x,eee-disabled;
			at803x,vddio-1p8v;
		};
	};
};

&flexspi0 { /* FLEXSPI0: MT35XU512ABA Octa-SPI */
	pinctrl-names = "default";
	pinctrl-0 = <&pinctrl_flexspi0>;
	#address-cells = <1>;
	#size-cells = <0>;
	fsl,spi-num-chipselects = <1>;
	status = "disabled";

	flash0: mt35xu512aba@0 {
		reg = <0>;
		#address-cells = <1>;
		#size-cells = <1>;
		compatible = "micron,mt35xu512aba";
		spi-max-frequency = <133000000>;
		spi-nor,ddr-quad-read-dummy = <8>;
		spi-tx-bus-width = <1>;
		spi-rx-bus-width = <1>;
		status = "disabled";
	};
};

&pciea{ /* PCIE: PCIEA SATA */
	ext_osc = <1>;
	pinctrl-names = "default";
	pinctrl-0 = <&pinctrl_pciea>;
	reset-gpio = <&lsio_gpio4 29 GPIO_ACTIVE_LOW>;
	reserved-region = <&rpmsg_reserved>;
	epdev_on-supply = <&reg_3p3v>;
	status = "okay";
};

&pcieb{ /* PCIE:  PCIEB SATA */
	ext_osc = <1>;
	epdev_on-supply = <&reg_3p3v>;
	status = "okay";
};

&rpmsg0{
	/*
	 * 64K for one rpmsg instance:
	 */
	vdev-nums = <2>;
	reg = <0x0 0x90000000 0x0 0x20000>;
	memory-region = <&rpmsg_dma_reserved>;
	status = "okay";
};

&rpmsg1{
	/*
	 * 64K for one rpmsg instance:
	 */
	vdev-nums = <2>;
	reg = <0x0 0x90100000 0x0 0x20000>;
	memory-region = <&rpmsg_dma_reserved>;
	status = "okay";
};

&sata { /* SATA */
	pinctrl-names = "default";
	pinctrl-0 = <&pinctrl_sata>;
	sata-act-gpios = <&lsio_gpio1 18 GPIO_ACTIVE_LOW>;
	fsl,phy-imp = <0x6c>;
	ext_osc = <1>;
	status = "okay";
};

&usbphy1 {
	status = "okay";
};

&usbotg1 { /* USBOTG1: USB 2.0 OTG Device */
	pinctrl-names = "default";
	pinctrl-0 = <&pinctrl_usbotg1>;
	srp-disable;
	hnp-disable;
	adp-disable;
	otg-pwr-gpio = <&lsio_gpio4 3 GPIO_ACTIVE_LOW>;
	dr_mode = "otg";
	power-polarity-active-high;
	disable-over-current;
	status = "okay";
};

&usb3phynop1 {
	status = "okay";
};

&usbotg3 { /* USBOTG3: USB Host */
	pinctrl-names = "default";
	pinctrl-0 = <&pinctrl_usbotg3>;
	vusb-supply = <&reg_usb_en>;
	dr_mode = "host";
	status = "okay";

};

&usdhc1 { /* USDHC1: EMMC */
	pinctrl-names = "default", "state_100mhz", "state_200mhz";
	pinctrl-0 = <&pinctrl_usdhc1>;
	pinctrl-1 = <&pinctrl_usdhc1>;
	pinctrl-2 = <&pinctrl_usdhc1>;
	bus-width = <8>;
	no-sd;
	no-sdio;
	non-removable;
	status = "okay";
};

&usdhc2 { /* USDHC2: Standard SD */
	pinctrl-names = "default", "state_100mhz", "state_200mhz";
	pinctrl-0 = <&pinctrl_usdhc2>, <&pinctrl_usdhc2_gpio>;
	pinctrl-1 = <&pinctrl_usdhc2>, <&pinctrl_usdhc2_gpio>;
	pinctrl-2 = <&pinctrl_usdhc2>, <&pinctrl_usdhc2_gpio>;
	bus-width = <4>;
	no-1-8-v;
	cd-gpios = <&lsio_gpio1 23 GPIO_ACTIVE_LOW>;
	wp-gpios = <&lsio_gpio1 22 GPIO_ACTIVE_HIGH>;
	vmmc-supply = <&reg_ssd_vmmc>;
	status = "okay";
};

&usdhc3 { /* USDHC3: SDIO JODY-W2 WIFI */
	pinctrl-names = "default","state_100mhz", "state_200mhz";
	pinctrl-0 = <&pinctrl_usdhc3>, <&pinctrl_usdhc3_gpio>;
	pinctrl-1 = <&pinctrl_usdhc3>, <&pinctrl_usdhc3_gpio>;
	pinctrl-2 = <&pinctrl_usdhc3>, <&pinctrl_usdhc3_gpio>;
	wifi-host-gpio = <&lsio_gpio3 12 GPIO_ACTIVE_HIGH>;
	wifi-dev-gpio = <&lsio_gpio3 5 GPIO_ACTIVE_HIGH>;
	bt-host-gpio = <&lsio_gpio3 0 GPIO_ACTIVE_HIGH>;
	bt-dev-gpio = <&lsio_gpio2 27 GPIO_ACTIVE_HIGH>;
	wl-en-gpio = <&lsio_gpio4 7 GPIO_ACTIVE_HIGH>;
	bt-en-gpio = <&lsio_gpio2 30 GPIO_ACTIVE_HIGH>;
	bus-width = <4>;
	vmmc-supply = <&reg_3p3v>;
	non-removable;
	fsl,tuning-start-tap = <40>;
        fsl,tuning-step= <2>;
	wifi-host;
	status = "okay";
};

&i2c1 { /* I2C: LPI2C1 */
	#address-cells = <1>;
	#size-cells = <0>;
	pinctrl-names = "default";
	pinctrl-0 = <&pinctrl_lpi2c1>;
	clock-frequency = <400000>;
	status = "okay";

        fusb302: usb-typec@22 {
		compatible = "fcs,fusb302";
		reg = <0x22>;
		pinctrl-names = "default";
		pinctrl-0 = <&pinctrl_type_c>;
		fcs,int_n = <&lsio_gpio0 0 IRQ_TYPE_LEVEL_LOW>;
		vbus-supply = <&vcc5v0_typec>;
		status = "okay";

		ports {
			#address-cells = <1>;
			#size-cells = <0>;

			port@1 {
				reg = <1>;
			};
		};

		usb_con1: connector {
			compatible = "usb-c-connector";
			label = "USB-C";
			power-role = "dual";
			data-role = "dual";
			try-power-role = "sink";
			source-pdos = <PDO_FIXED(5000, 400, PDO_FIXED_DUAL_ROLE | PDO_FIXED_DATA_SWAP | PDO_FIXED_USB_COMM)>;
			sink-pdos = <PDO_FIXED(5000, 400, PDO_FIXED_DUAL_ROLE | PDO_FIXED_DATA_SWAP | PDO_FIXED_USB_COMM)>;
			op-sink-microwatt = <25000000>;

			ports {
				#address-cells = <1>;
				#size-cells = <0>;

				port@1 {
				        reg = <1>;
				        typec_con_ss: endpoint {
				                remote-endpoint = <&usb_data_ss>;
					};
				};
			};
		};
	};

	codec: sgtl5000@a { /* SGTL5000: Audio Codec */
		compatible = "fsl,sgtl5000";
		reg = <0x0a>;
		pinctrl-names = "default";
		pinctrl-0 = <&pinctrl_hp_mic_detect>;
		clocks = <&audioclk 0>;
		VDDA-supply = <&reg_1p8v>;
		VDDIO-supply = <&reg_1p8v>;
		VDDD-supply = <&reg_1p5v>;
		power-domains = <&pd IMX_SC_R_MCLK_OUT_0>;
		hp-det-gpios = <&lsio_gpio0 2 GPIO_ACTIVE_LOW>;
		mic-det-gpios = <&lsio_gpio0 5 GPIO_ACTIVE_LOW>;
		status = "okay";
	};
};

&irqsteer_lvds0 {
	status = "okay";
};

&i2c1_lvds0 { /* I2C1 LVDS0: Touch I2C for B0 CPU */
	reg = <0x56246000 0x4000>;
	interrupts = <8>;
	#address-cells = <1>;
	#size-cells = <0>;
	pinctrl-names = "default";
	pinctrl-0 = <&pinctrl_i2c1_lvds0>;
	clock-frequency = <400000>;
	status = "okay";

	cst148@1a { /* Touch: Hynitron Touch panel (1080p display) */
		compatible = "hynitron,cst1xx";
		reg = <0x1a>;
		interrupt-parent = <&lsio_gpio0>;
		interrupts = <1 2>;
		vdd_ana-supply = <&reg_3p3v>;
		vcc_i2c-supply = <&reg_3p3v>;
		hynitron,panel-coords = <0 1080 0 1920>;
		hynitron,display-coords = <0 1080 0 1920>;
		pinctrl-names = "default";
		pinctrl-0 = <&pinctrl_ts_active_iwg27m>;
		hynitron,irq-gpio = <&lsio_gpio0 1 GPIO_ACTIVE_LOW>;
		hynitron,rst-gpio = <&lsio_gpio0 10 GPIO_ACTIVE_LOW>;
		report_type = <1>;
		status = "okay";
	};
};

/* Multimedia: Image Sensing Interface */
&isi_0 {
	status = "okay";

	cap_device {
		status = "okay";
	};

	m2m_device {
		status = "okay";
	};
};

&isi_1 {
	status = "disabled";

	cap_device {
		status = "disabled";
	};
};

/* HDMI: HDMI-RX */
&isi_2 {
	interface = <4 0 2>;  /* <Input MIPI_VCx Output>
				Input:  0-DC0, 1-DC1, 2-MIPI CSI0, 3-MIPI CSI1, 4-HDMI, 5-MEM
				VCx:    0-VC0, 1-VC1, 2-VC2, 3-VC3, MIPI CSI only
				Output: 0-DC0, 1-DC1, 2-MEM */
	 status = "disabled";

	cap_device {
		status = "disabled";
	};
};

&isi_3 {
	/* For HDMI RX 4K chain buf */
	interface = <4 0 2>;
	status = "disabled";

	cap_device {
		status = "disabled";
	};
};

&isi_4 {
	status = "okay";

	cap_device {
		status = "okay";
	};
};

&isi_5 {
	status = "disabled";

	cap_device {
		status = "disabled";
	};
};

&isi_6 {
	status = "disabled";

	cap_device {
		status = "disabled";
	};
};

&isi_7 {
	status = "disabled";

	cap_device {
		status = "disabled";
	};
};

&irqsteer_csi0 {
	status = "okay";
};

&mipi_csi_0 { /* MIPI_CSI0: OV5640 Camera */
	#address-cells = <1>;
	#size-cells = <0>;
	status = "okay";

	port@0 {
		reg = <0>;
		mipi_csi0_ep: endpoint {
			remote-endpoint = <&ov5640_mipi_ep>;
			data-lanes = <1 2>;
			bus-type = <4>;
		};
	};
};

&jpegdec {
       status = "okay";
};

&jpegenc {
       status = "okay";
};

&i2c_mipi_csi0 { /* MIPI_CSI0: OV5640 Camera */
	#address-cells = <1>;
	#size-cells = <0>;
	pinctrl-names = "default";
	clock-frequency = <400000>;
	status = "okay";

	ov5640_mipi: ov5640_mipi@3c {
		compatible = "ovti,ov5640";
		reg = <0x3c>;
		pinctrl-names = "default";
		pinctrl-0 = <&pinctrl_mipi_csi0>;
		clocks = <&xtal24m>;
		clock-names = "xclk";
		mclk = <24000000>;
		mclk_source = <0>;
		mipi_csi;
		status = "okay";
		port {
			ov5640_mipi_ep: endpoint {
			remote-endpoint = <&mipi_csi0_ep>;
			data-lanes = <1 2>;
			clocks-lanes = <0>;
			};
		};
	};
};


&thermal_zones { /* Thermal Sensor Zone */
	pmic-thermal0 {
		polling-delay-passive = <250>;
		polling-delay = <2000>;
		thermal-sensors = <&tsens IMX_SC_R_PMIC_0>;
		trips {
			pmic_alert0: trip0 {
				temperature = <110000>;
				hysteresis = <2000>;
				type = "passive";
			};
			pmic_crit0: trip1 {
				temperature = <125000>;
				hysteresis = <2000>;
				type = "critical";
			};
		};
		cooling-maps {
			map0 {
				trip = <&pmic_alert0>;
				cooling-device =
				<&A53_0 THERMAL_NO_LIMIT THERMAL_NO_LIMIT>,
				<&A53_1 THERMAL_NO_LIMIT THERMAL_NO_LIMIT>,
				<&A53_2 THERMAL_NO_LIMIT THERMAL_NO_LIMIT>,
				<&A53_3 THERMAL_NO_LIMIT THERMAL_NO_LIMIT>,
				<&A72_0 THERMAL_NO_LIMIT THERMAL_NO_LIMIT>,
				<&A72_1 THERMAL_NO_LIMIT THERMAL_NO_LIMIT>;
			};
		};
	};
};

/* Graphics Processing Unit: GPU 3D,2D */
&gpu_3d0 {
	status = "okay";
};

&gpu_3d1 {
	status = "okay";
};

&imx8_gpu_ss {
	status = "okay";
};

&dpu2 {
	status = "okay";
};

&mu_m0{
	interrupts = <GIC_SPI 472 IRQ_TYPE_LEVEL_HIGH>;
};

&mu1_m0{
	interrupts = <GIC_SPI 473 IRQ_TYPE_LEVEL_HIGH>;
};

&mu2_m0{
	interrupts = <GIC_SPI 474 IRQ_TYPE_LEVEL_HIGH>;
	status = "okay";
};

&vpu_decoder {
	compatible = "nxp,imx8qm-b0-vpudec";
	boot-region = <&decoder_boot>;
	rpc-region = <&decoder_rpc>;
	reg-csr = <0x2d080000>;
	core_type = <2>;
	status = "okay";
};

&vpu_encoder {
        compatible = "nxp,imx8qm-b0-vpuenc";
        boot-region = <&encoder_boot>;
        rpc-region = <&encoder_rpc>;
        reserved-region = <&encoder_reserved>;
        reg-rpc-system = <0x40000000>;
        resolution-max = <1920 1080>;
        power-domains = <&pd IMX_SC_R_VPU_ENC_0>, <&pd IMX_SC_R_VPU_ENC_1>,
                        <&pd IMX_SC_R_VPU>;
        power-domain-names = "vpuenc1", "vpuenc2", "vpu";
        mbox-names = "enc1_tx0", "enc1_tx1", "enc1_rx",
                     "enc2_tx0", "enc2_tx1", "enc2_rx";
        mboxes = <&mu1_m0 0 0
                  &mu1_m0 0 1
                  &mu1_m0 1 0
                  &mu2_m0 0 0
                  &mu2_m0 0 1
                  &mu2_m0 1 0>;
        status = "okay";

        core0@1020000 {
                compatible = "fsl,imx8-mu1-vpu-m0";
                reg = <0x1020000 0x20000>;
                reg-csr = <0x1090000 0x10000>;
                interrupts = <GIC_SPI 473 IRQ_TYPE_LEVEL_HIGH>;
                fsl,vpu_ap_mu_id = <17>;
                fw-buf-size = <0x200000>;
                rpc-buf-size = <0x80000>;
                print-buf-size = <0x80000>;
        };

        core1@1040000 {
                compatible = "fsl,imx8-mu2-vpu-m0";
                reg = <0x1040000 0x20000>;
                reg-csr = <0x10A0000 0x10000>;
                interrupts = <GIC_SPI 474 IRQ_TYPE_LEVEL_HIGH>;
                fsl,vpu_ap_mu_id = <18>;
                fw-buf-size = <0x200000>;
                rpc-buf-size = <0x80000>;
                print-buf-size = <0x80000>;
        };
};

&unused_gpios { /* GPIO: iWave Unused GPIO pins */
	gpios = <&lsio_gpio1 4 0>,
		<&lsio_gpio1 8 0>,
		<&lsio_gpio1 10 0>,
		<&lsio_gpio1 14 0>,
		<&lsio_gpio1 15 0>,
		<&lsio_gpio1 29 0>,
		<&lsio_gpio2 0 0>,
		<&lsio_gpio2 1 0>,
		<&lsio_gpio2 2 0>,
		<&lsio_gpio2 3 0>,
		<&lsio_gpio2 4 0>,
		<&lsio_gpio2 5 0>,
		<&lsio_gpio2 6 0>,
		<&lsio_gpio2 7 0>,
		<&lsio_gpio2 8 0>,
		<&lsio_gpio2 9 0>,
		<&lsio_gpio2 10 0>,
		<&lsio_gpio2 11 0>,
		<&lsio_gpio2 12 0>,
		<&lsio_gpio2 13 0>,
		<&lsio_gpio2 14 0>,
		<&lsio_gpio2 15 0>,
		<&lsio_gpio2 16 0>,
		<&lsio_gpio2 22 0>,
		<&lsio_gpio2 24 0>,
		<&lsio_gpio3 2 0>,
		<&lsio_gpio3 3 0>,
		<&lsio_gpio3 4 0>,
		<&lsio_gpio3 6 0>,
		<&lsio_gpio3 11 0>,
		<&lsio_gpio3 14 0>,
		<&lsio_gpio3 23 0>,
		<&lsio_gpio3 24 0>,
		<&lsio_gpio3 25 0>,
		<&lsio_gpio3 26 0>,
		<&lsio_gpio3 27 0>,
		<&lsio_gpio3 28 0>,
		<&lsio_gpio4 1 0>,
		<&lsio_gpio4 2 0>,
		<&lsio_gpio4 5 0>,
		<&lsio_gpio4 9 0>,
		<&lsio_gpio4 19 0>,
		<&lsio_gpio4 20 0>,
		<&lsio_gpio4 21 0>,
		<&lsio_gpio4 22 0>,
		<&lsio_gpio4 23 0>,
		<&lsio_gpio4 24 0>,
		<&lsio_gpio4 25 0>,
		<&lsio_gpio4 26 0>,
		<&lsio_gpio5 1 0>,
		<&lsio_gpio5 2 0>,
		<&lsio_gpio5 19 0>,
		<&lsio_gpio5 20 0>,
		<&lsio_gpio5 21 0>,
		<&lsio_gpio5 22 0>;
};
